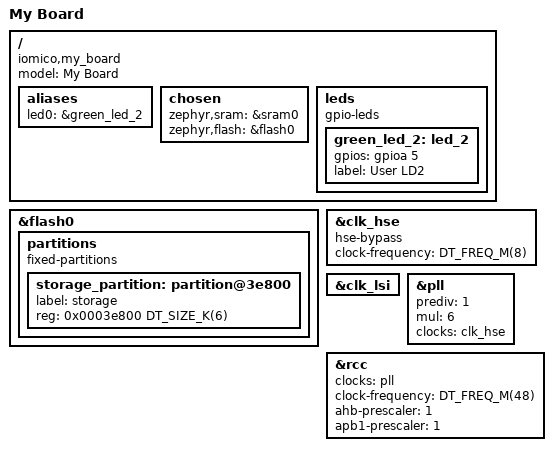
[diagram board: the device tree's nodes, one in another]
/dts-v1/;

#include <st/f0/stm32f091Xc.dtsi>
#include <st/f0/stm32f091r(b-c)tx-pinctrl.dtsi>

/ {
    model = "My Board";
	compatible = "iomico,my_board";

    aliases {
		led0 = &green_led_2;
    };

    chosen {
		zephyr,sram = &sram0;
		zephyr,flash = &flash0;
    };

    leds: leds {
		compatible = "gpio-leds";

		green_led_2: led_2 {
			gpios = <&gpioa 5 GPIO_ACTIVE_HIGH>;
			label = "User LD2";
		};
	};
};

&flash0 {
    partitions {
        compatible = "fixed-partitions";
        #address-cells = <1>;
        #size-cells = <1>;

        /* Set 6Kb of storage at the end of the 256Kb of flash */
        storage_partition: partition@3e800 {
            label = "storage";
            reg = <0x0003e800 DT_SIZE_K(6)>;
        };
    };
};

&clk_hse {
	hse-bypass;
	clock-frequency = <DT_FREQ_M(8)>; /* STLink 8MHz clock */
	status = "okay";
};

&clk_lsi {
	status = "okay";
};

&pll {
	prediv = <1>;
	mul = <6>;
	clocks = <&clk_hse>;
	status = "okay";
};

&rcc {
	clocks = <&pll>;
	clock-frequency = <DT_FREQ_M(48)>;
	ahb-prescaler = <1>;
	apb1-prescaler = <1>;
};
